# MKM34Z7 register map
Vendor: Freescale Semiconductor, Inc.; Series: Kinetis_M; File version: 1.6
CPU: CM0PLUS r0p0, little endian, no MPU, no FPU, VTOR, 2 interrupt priority bits
Registers are 32-bit, read-write, reset 0x0 unless marked. A register's access mark holds for its fields unless they carry their own. Offsets are from the block's base; [hi:lo] are bit positions; {n}, {i} and the like mark numbered series.

## DMAMUX0 — DMA channel multiplexor
Base 0x40021000; register names take the prefix DMAMUX0_
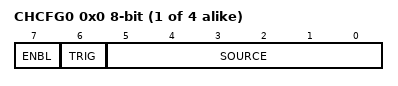
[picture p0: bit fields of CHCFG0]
{0x0+i} CHCFG{i} (i=0..3) 8-bit — Channel Configuration register
  [7] ENBL — DMA Channel Enable
    0=DMA channel is disabled. This mode is primarily used during configuration of the DMAMux. The DMA has separate channel enables/disables, which should be used to disable or reconfigure a DMA channel.; 1=DMA channel is enabled
  [6] TRIG — DMA Channel Trigger Enable
    0=Triggering is disabled. If triggering is disabled and ENBL is set, the DMA Channel will simply route the specified source to the DMA channel. (Normal mode); 1=Triggering is enabled. If triggering is enabled and ENBL is set, the DMAMUX is in Periodic Trigger mode.
  [5:0] SOURCE — DMA Channel Source (Slot)
    0=Disable_Signal; 2=UART0_Rx_Signal; 3=UART0_Tx_Signal; 4=UART1_Rx_Signal; 5=UART1_Tx_Signal; 6=UART2_Rx_Signal; 7=UART2_Tx_Signal; 8=UART3_Rx_Signal; 9=UART3_Tx_Signal; 16=SPI0_Rx_Signal; 17=SPI0_Tx_Signal; 18=SPI1_Rx_Signal; 19=SPI1_Tx_Signal; 22=I2C0_Signal; 23=I2C1_Signal; {v}=TMR0_Channel{v-24}_Signal (v=24..27); {v}=XBAR_Request{v-28}_Signal (v=28..31); {v}=AFE_Channel{v-32}_Signal (v=32..35); 36=Port_J_Signal; 37=Port_K_Signal; 38=Port_L_Signal; 39=Port_M_Signal; 40=SarADC_Signal; 42=CMP0_Signal; 43=CMP1_Signal; 44=CMP2_Signal; 47=MMAU_Signal; 48=PDB0_Signal; 49=PORT_A_Signal; 50=PORT_B_Signal; 51=PORT_C_Signal; 52=PORT_D_Signal; 53=PORT_E_Signal; 54=PORT_F_Signal; 55=PORT_G_Signal; 56=PORT_H_Signal; 57=PORT_I_Signal; 58=LPUART0_Rx_Signal; 59=LPUART0_Tx_Signal; {v}=AlwaysOn{v}_Signal (v=60..63)

## RNG — Random Number Generator Accelerator
Base 0x40029000; register names take the prefix RNG_
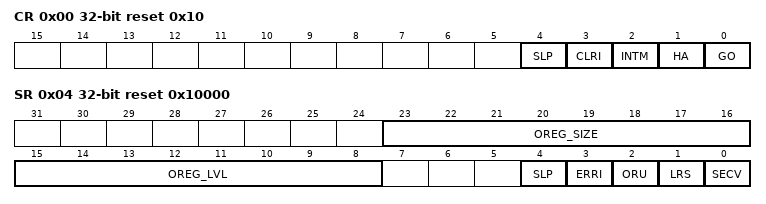
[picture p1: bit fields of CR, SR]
0x00 CR reset 0x10 — RNGA Control Register
  [4] SLP — Sleep
    0=Normal mode; 1=Sleep (low-power) mode
  [3] CLRI wo — Clear Interrupt
    0=Do not clear the interrupt; 1=Clear the interrupt. When you write 1 to this field, RNGA then resets the error-interrupt indicator (SR[ERRI]). This bit always reads as 0.
  [2] INTM — Interrupt Mask
    0=Not masked; 1=Masked
  [1] HA — High Assurance
    0=Disabled; 1=Enabled
  [0] GO
    0=Disabled; 1=Enabled
0x04 SR ro reset 0x10000 — RNGA Status Register
  [23:16] OREG_SIZE — Output Register Size
    1=One word (this value is fixed)
  [15:8] OREG_LVL — Output Register Level
    0=No words (empty); 1=One word (valid)
  [4] SLP — Sleep
    0=Normal mode; 1=Sleep (low-power) mode
  [3] ERRI — Error Interrupt
    0=No underflow; 1=Underflow
  [2] ORU — Output Register Underflow
    0=No underflow; 1=Underflow
  [1] LRS — Last Read Status
    0=No underflow; 1=Underflow
  [0] SECV — Security Violation
    0=No security violation; 1=Security violation
0x08 ER wo — RNGA Entropy Register
  [31:0] EXT_ENT — External Entropy
0x0C OR ro — RNGA Output Register
  [31:0] RANDOUT — Random Output
    0=Invalid data (if you read this field when it is 0 and SR[OREG_LVL] is 0, RNGA then writes 1 to SR[ERRI], SR[ORU], and SR[LRS]; when the error interrupt is not masked (CR[INTM]=0), RNGA also asserts an error interrupt request to the interrupt controller)

## PIT0 — Periodic Interrupt Timer
Base 0x4002D000; register names take the prefix PIT0_
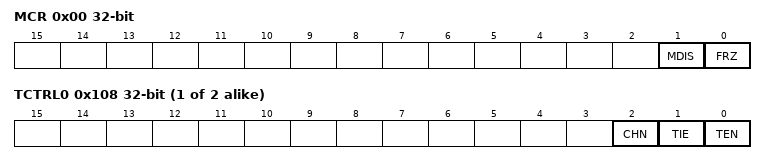
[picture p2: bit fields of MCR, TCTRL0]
0x00 MCR — PIT Module Control Register
  [1] MDIS — Module Disable - (PIT section)
    0=Clock for standard PIT timers is enabled; 1=Clock for standard PIT timers is disabled
  [0] FRZ — Freeze
    0=Timers continue to run in Debug mode; 1=Timers are stopped in Debug mode
{0x100+0x10*i} LDVAL{i} (i=0..1) — Timer Load Value Register
  [31:0] TSV — Timer Start Value
{0x104+0x10*i} CVAL{i} (i=0..1) ro — Current Timer Value Register
  [31:0] TVL — Current Timer Value
{0x108+0x10*i} TCTRL{i} (i=0..1) — Timer Control Register
  [2] CHN — Chain Mode
    0=Timer is not chained; 1=Timer is chained to previous timer. For example, for Channel 2, if this field is set, Timer 2 is chained to Timer 1.
  [1] TIE — Timer Interrupt Enable
    0=Interrupt requests from Timer n are disabled; 1=Interrupt will be requested whenever TIF is set
  [0] TEN — Timer Enable
    0=Timer n is disabled; 1=Timer n is enabled
{0x10C+0x10*i} TFLG{i} (i=0..1) — Timer Flag Register
  [0] TIF — Timer Interrupt Flag
    0=Timeout has not yet occurred; 1=Timeout has occurred

## PIT1 — Periodic Interrupt Timer
Base 0x4002E000; register names take the prefix PIT1_
Registers as PIT0.
